# STM32L552xx register map
File version: 1.0
Registers are 32-bit, read-write, reset 0x0 unless marked. A register's access mark holds for its fields unless they carry their own. Offsets are from the block's base; [hi:lo] are bit positions.

## UCPD1 — UCPD
Base 0x4000DC00
Same registers: UCPD1_S 0x5000DC00
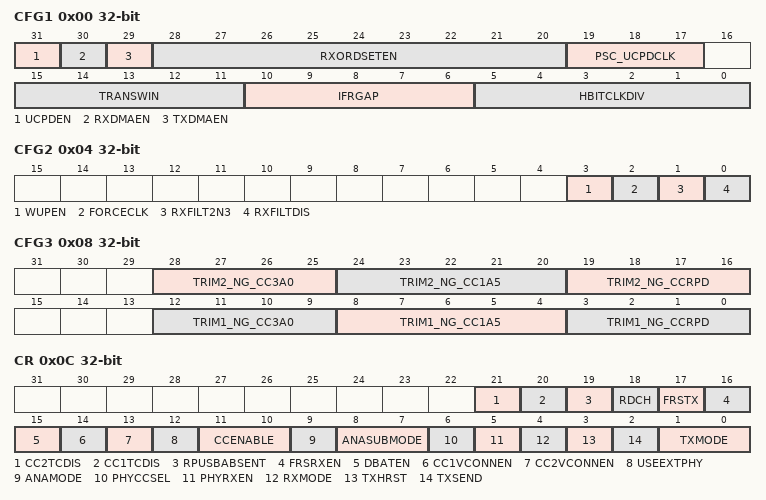
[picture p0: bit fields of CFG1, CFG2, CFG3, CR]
0x00 CFG1 — UCPD configuration register 1
  [31] UCPDEN — USB Power Delivery Block Enable
  [30] RXDMAEN — DMA reception requests enable
  [29] TXDMAEN — DMA transmission requests enable
  [28:20] RXORDSETEN — Receiver ordered set detection enable
    1=SOP (SOP Ordered set detection enabled); 2=SOP1 (SOP' Ordered set detection enabled); 4=SOP2 (SOP'' Ordered set detection enabled); 8=HARDRST (Hard Reset Ordered set detection enabled); 16=CABLERST (Cable Reset Ordered set detection enabled); 32=SOP1_DEBUG (SOP' Debug Ordered set detection enabled); 64=SOP2_DEBUG (SOP'' Debug Ordered set detection enabled); 128=SOP_EXT1 (SOP extension#1 Ordered set detection enabled); 0x100=SOP_EXT2 (SOP extension#2 Ordered set detection enabled)
  [19:17] PSC_UCPDCLK — Prescaler for UCPDCLK
    0=DIV1 (Bypass pre-scaling / divide by 1); 1=DIV2 (Pre-scale clock by dividing by 2); 2=DIV4 (Pre-scale clock by dividing by 4); 3=DIV8 (Pre-scale clock by dividing by 8); 4=DIV16 (Pre-scale clock by dividing by 16)
  [15:11] TRANSWIN — Number of cycles (minus 1) of the half bit clock
  [10:6] IFRGAP — Clock divider value to generates Interframe gap
  [5:0] HBITCLKDIV — Number of cycles (minus 1) for a half bit clock
0x04 CFG2 — UCPD configuration register 2
  [3] WUPEN — Wakeup from STOP enable
  [2] FORCECLK — Controls forcing of the clock request UCPDCLK_REQ
  [1] RXFILT2N3 — Controls the sampling method for an Rx pre-filter for the BMC decode
  [0] RXFILTDIS — Enables an Rx pre-filter for the BMC decoder
0x08 CFG3 — UCPD configuration register 3
  [28:25] TRIM2_NG_CC3A0 — SW trim value for RP3A0 resistors (CC1)
  [24:20] TRIM2_NG_CC1A5 — SW trim value for RP1A5 resistors (CC1)
  [19:16] TRIM2_NG_CCRPD — SW trim value for RPDEFAULT resistors (CC1)
  [12:9] TRIM1_NG_CC3A0 — SW trim value for RP3A0 resistors (CC1)
  [8:4] TRIM1_NG_CC1A5 — SW trim value for RP1A5 resistors (CC1)
  [3:0] TRIM1_NG_CCRPD — SW trim value for RPDEFAULT resistors (CC1)
0x0C CR — UCPD control register
  [21] CC2TCDIS — The bit allows the Type-C detector for CC2 to be disabled
  [20] CC1TCDIS — The bit allows the Type-C detector for CC0 to be disabled
  [19] RPUSBABSENT
  [18] RDCH
  [17] FRSTX — Signal Fast Role Swap request
  [16] FRSRXEN — Enable FRS request detection function
  [15] DBATEN — Enable dead battery behavior (Active High)
  [14] CC1VCONNEN — VCONN enable for CC1
  [13] CC2VCONNEN — VCONN enable for CC2
  [12] USEEXTPHY — Controls enable of USB Power Delivery transmitter
  [11:10] CCENABLE
    0=NONE (Neither PHY is activated (e.g. disabled state of source)); 1=CC1 (Controls apply to only CC1); 2=CC2 (Controls apply to only CC1); 3=CC1CC2 (Controls apply to both CC1 and CC2 (normal usage for sink/source))
  [9] ANAMODE — Analog PHY working mode
    1=SNK (Mode SNK Rd); 0=SRC (Mode SRC Rp)
  [8:7] ANASUBMODE — Analog PHY sub-mode
    1=DEFAULT (Rp default); 2=RESISTOR_1_5A (Rp 1.5 A); 3=RESISTOR_3_0A (Rp 3.0 A); 0=NONE (No resistor)
  [6] PHYCCSEL
    0=CC1 (Use CC1 IO for power delivery communication); 1=CC2 (Use CC2 IO for power delivery communication)
  [5] PHYRXEN — Controls enable of USB Power Delivery receiver
  [4] RXMODE — Receiver mode
    0=NORMAL (Normal receive mode); 1=BIST_TEST_DATA (BIST receive mode (BIST Test Data Mode))
  [3] TXHRST — Command to send a Tx Hard Reset
  [2] TXSEND — Type of Tx packet
  [1:0] TXMODE — Type of Tx packet
    0=NORMAL (Initiate the transfer of a Tx message); 1=CABLE_RESET (Trigger a the transfer of a Cable Reset sequence); 2=BIST_CARRIER2 (Trigger a BIST test sequence send (BIST Carrier Mode 2))
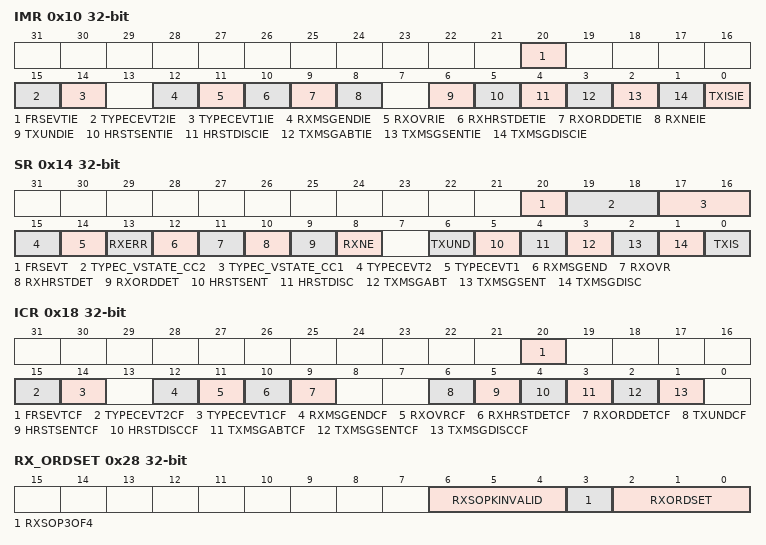
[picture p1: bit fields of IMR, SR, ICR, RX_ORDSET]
0x10 IMR — UCPD interrupt mask register
  [20] FRSEVTIE — Fast Role Swap interrupt
  [15] TYPECEVT2IE — Enable TYPECEVT2IE interrupt
  [14] TYPECEVT1IE — Enable TYPECEVT1IE interrupt
  [12] RXMSGENDIE — Enable RXMSGEND interrupt
  [11] RXOVRIE — Enable RXOVR interrupt
  [10] RXHRSTDETIE — Enable RXHRSTDET interrupt
  [9] RXORDDETIE — Enable RXORDDET interrupt
  [8] RXNEIE — Enable RXNE interrupt
  [6] TXUNDIE — Enable TXUND interrupt
  [5] HRSTSENTIE — Enable HRSTSENT interrupt
  [4] HRSTDISCIE — Enable HRSTDISC interrupt
  [3] TXMSGABTIE — Enable TXMSGABT interrupt
  [2] TXMSGSENTIE — Enable TXMSGSENT interrupt
  [1] TXMSGDISCIE — Enable TXMSGDISC interrupt
  [0] TXISIE — Enable TXIS interrupt
0x14 SR — UCPD status register
  [20] FRSEVT — Fast Role Swap detection event
  [19:18] TYPEC_VSTATE_CC2 — Status of DC level on CC2 pin
  [17:16] TYPEC_VSTATE_CC1 — Status of DC level on CC1 pin
  [15] TYPECEVT2 — Type C voltage level event on CC2
  [14] TYPECEVT1 — Type C voltage level event on CC1
  [13] RXERR — RX Error
  [12] RXMSGEND — Rx message received
  [11] RXOVR — Rx data overflow interrupt
  [10] RXHRSTDET — Rx Hard Reset detect interrupt
  [9] RXORDDET — Rx ordered set (4 K-codes) detected interrupt
  [8] RXNE — Receive data register not empty interrupt
  [6] TXUND — Tx data underrun condition interrupt
  [5] HRSTSENT — HRST sent interrupt
  [4] HRSTDISC — HRST discarded interrupt
  [3] TXMSGABT — Transmit message abort interrupt
  [2] TXMSGSENT — Transmit message sent interrupt
  [1] TXMSGDISC — Transmit message discarded interrupt
  [0] TXIS — Transmit interrupt status
0x18 ICR — UCPD interrupt flag clear register
  [20] FRSEVTCF — Fast Role Swap event flag clear
  [15] TYPECEVT2CF — TypeC event (CC2) flag (TYPECEVT2) clear
  [14] TYPECEVT1CF — TypeC event (CC1) flag (TYPECEVT1) clear
  [12] RXMSGENDCF — Rx message received flag (RXMSGEND) clear
  [11] RXOVRCF — Rx overflow flag (RXOVR) clear
  [10] RXHRSTDETCF — Rx Hard Reset detected flag (RXHRSTDET) clear
  [9] RXORDDETCF — Rx ordered set detect flag (RXORDDET) clear
  [6] TXUNDCF — Tx underflow flag (TXUND) clear
  [5] HRSTSENTCF — Hard reset sent flag (HRSTSENT) clear
  [4] HRSTDISCCF — Hard reset discarded flag (HRSTDISC) clear
  [3] TXMSGABTCF — Tx message abort flag (TXMSGABT) clear
  [2] TXMSGSENTCF — Tx message sent flag (TXMSGSENT) clear
  [1] TXMSGDISCCF — Tx message discarded flag (TXMSGDISC) clear
0x1C TX_ORDSET — UCPD Tx ordered set type register
  [19:0] TXORDSET — Tx Ordered Set
0x20 TX_PAYSZ — UCPD Tx payload size register
  [9:0] TXPAYSZ — Tx payload size in bytes
0x24 TXDR — UCPD Tx data register
  [7:0] TXDATA
0x28 RX_ORDSET — UCPD Rx ordered set type register
  [6:4] RXSOPKINVALID — Rx Ordered Set corrupted K-Codes (Debug)
  [3] RXSOP3OF4 — Rx Ordered Set Debug indication
  [2:0] RXORDSET — Rx Ordered Set Code detected
    0=SOP (SOP code detected in receiver); 1=SOP1 (SOP' code detected in receiver); 2=SOP2 (SOP'' code detected in receiver); 3=SOP1_DEBUG (SOP' Debug code detected in receiver); 4=SOP2_DEBUG (SOP'' Debug code detected in receiver); 5=CABLE_RESET (Cable Reset code detected in receiver); 6=SOPEXT1 (SOP extension#1 code detected in receiver); 7=SOPEXT2 (SOP extension#2 code detected in receiver)
0x2C RX_PAYSZ — UCPD Rx payload size register
  [9:0] RXPAYSZ — Rx payload size in bytes
0x30 RXDR — UCPD Rx data register
  [7:0] RXDATA — 8-bit receive data
0x34 RX_ORDEXT1 — UCPD Rx ordered set extension 1 register
  [19:0] RXSOPX1 — RX Ordered Set Extension Register 1
0x38 RX_ORDEXT2 — UCPD Rx ordered set extension 2 register
  [19:0] RXSOPX2 — RX Ordered Set Extension Register 1
